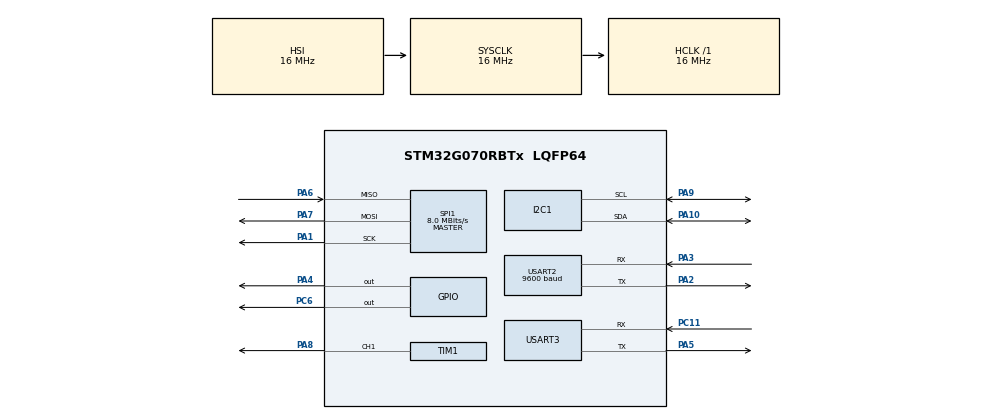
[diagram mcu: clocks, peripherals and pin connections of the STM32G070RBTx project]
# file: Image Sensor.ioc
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Dma.Request0=SPI1_RX
Dma.Request1=SPI1_TX
Dma.SPI1_RX.0.Direction=DMA_PERIPH_TO_MEMORY
Dma.SPI1_RX.0.EventEnable=DISABLE
Dma.SPI1_RX.0.Instance=DMA1_Channel1
Dma.SPI1_RX.0.MemDataAlignment=DMA_MDATAALIGN_BYTE
Dma.SPI1_RX.0.MemInc=DMA_MINC_ENABLE
Dma.SPI1_RX.0.Mode=DMA_NORMAL
Dma.SPI1_RX.0.PeriphDataAlignment=DMA_PDATAALIGN_BYTE
Dma.SPI1_RX.0.PeriphInc=DMA_PINC_DISABLE
Dma.SPI1_RX.0.Polarity=HAL_DMAMUX_REQ_GEN_RISING
Dma.SPI1_RX.0.Priority=DMA_PRIORITY_HIGH
Dma.SPI1_RX.0.RequestNumber=1
Dma.SPI1_RX.0.SignalID=NONE
Dma.SPI1_RX.0.SyncEnable=DISABLE
Dma.SPI1_RX.0.SyncPolarity=HAL_DMAMUX_SYNC_NO_EVENT
Dma.SPI1_RX.0.SyncRequestNumber=1
Dma.SPI1_RX.0.SyncSignalID=NONE
Dma.SPI1_TX.1.Direction=DMA_MEMORY_TO_PERIPH
Dma.SPI1_TX.1.EventEnable=DISABLE
Dma.SPI1_TX.1.Instance=DMA1_Channel2
Dma.SPI1_TX.1.MemDataAlignment=DMA_MDATAALIGN_BYTE
Dma.SPI1_TX.1.MemInc=DMA_MINC_ENABLE
Dma.SPI1_TX.1.Mode=DMA_NORMAL
Dma.SPI1_TX.1.PeriphDataAlignment=DMA_PDATAALIGN_BYTE
Dma.SPI1_TX.1.PeriphInc=DMA_PINC_DISABLE
Dma.SPI1_TX.1.Polarity=HAL_DMAMUX_REQ_GEN_RISING
Dma.SPI1_TX.1.Priority=DMA_PRIORITY_HIGH
Dma.SPI1_TX.1.RequestNumber=1
Dma.SPI1_TX.1.SignalID=NONE
Dma.SPI1_TX.1.SyncEnable=DISABLE
Dma.SPI1_TX.1.SyncPolarity=HAL_DMAMUX_SYNC_NO_EVENT
Dma.SPI1_TX.1.SyncRequestNumber=1
Dma.SPI1_TX.1.SyncSignalID=NONE
Mcu.Family=STM32G0
Mcu.Name=STM32G070RBTx
Mcu.Package=LQFP64
NVIC.DMA1_Channel1_IRQn=true\:0\:0\:false\:false\:true\:false\:true\:true
NVIC.DMA1_Channel2_3_IRQn=true\:0\:0\:false\:false\:true\:false\:true\:true
PA1.Mode=Full_Duplex_Master
PA1.Signal=SPI1_SCK
PA10.Mode=I2C
PA10.Signal=I2C1_SDA
PA2.Mode=Asynchronous
PA2.Signal=USART2_TX
PA3.Mode=Asynchronous
PA3.Signal=USART2_RX
PA4.Signal=GPIO_Output
PA5.Mode=Asynchronous
PA5.Signal=USART3_TX
PA6.Mode=Full_Duplex_Master
PA6.Signal=SPI1_MISO
PA7.Mode=Full_Duplex_Master
PA7.Signal=SPI1_MOSI
PA8.Signal=S_TIM1_CH1
PA9.Mode=I2C
PA9.Signal=I2C1_SCL
PC11.Mode=Asynchronous
PC11.Signal=USART3_RX
PC6.Signal=GPIO_Output
ProjectManager.HeapSize=0x200
ProjectManager.StackSize=0x400
ProjectManager.TargetToolchain=STM32CubeIDE
RCC.ADCFreq_Value=16000000
RCC.AHBFreq_Value=16000000
RCC.CortexFreq_Value=16000000
RCC.EXTERNAL_CLOCK_VALUE=48000
RCC.HCLKFreq_Value=16000000
RCC.HSE_VALUE=8000000
RCC.HSI_VALUE=16000000
RCC.LSE_VALUE=32768
RCC.PLLM=RCC_PLLM_DIV2
RCC.PLLN=20
RCC.PLLR=RCC_PLLR_DIV4
RCC.SYSCLKFreq_VALUE=16000000
RCC.VCOOutputFreq_Value=160000000
SH.S_TIM1_CH1.0=TIM1_CH1,PWM Generation1 CH1
SPI1.BaudRatePrescaler=SPI_BAUDRATEPRESCALER_2
SPI1.CalculateBaudRate=8.0 MBits/s
SPI1.DataSize=SPI_DATASIZE_8BIT
SPI1.Direction=SPI_DIRECTION_2LINES
SPI1.Mode=SPI_MODE_MASTER
SPI1.VirtualType=VM_MASTER
TIM1.Channel-PWM\ Generation1\ CH1=TIM_CHANNEL_1
TIM1.Period=1000-1
TIM1.Prescaler=320-1
TIM1.Pulse-PWM\ Generation1\ CH1=25
TIM3.Period=0xffff-1
TIM3.Prescaler=16-1
USART2.BaudRate=9600
USART2.VirtualMode-Asynchronous=VM_ASYNC
USART3.VirtualMode-Asynchronous=VM_ASYNC
VP_SYS_VS_DBSignals.Mode=DisableDeadBatterySignals
VP_TIM3_VS_ClockSourceINT.Mode=Internal
board=custom

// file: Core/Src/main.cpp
/* USER CODE BEGIN Header */
/**
  ******************************************************************************
  * @file           : main.c
  * @brief          : Main program body
  ******************************************************************************
  * @attention
  *
  * Copyright (c) 2024 STMicroelectronics.
  * All rights reserved.
  *
  * This software is licensed under terms that can be found in the LICENSE file
  * in the root directory of this software component.
  * If no LICENSE file comes with this software, it is provided AS-IS.
  *
  ******************************************************************************
  */
/* USER CODE END Header */
extern "C"{
#include "main.h"
}

/* USER CODE BEGIN Includes */
extern "C"{
#include "stm32g0xx_hal_conf.h"
}
#include <string.h>
#include "../Camera_driver/inc/OV2640_regs.hpp"
#include "../Camera_driver/inc/SPI_camera.hpp"
#include "../Camera_driver/inc/OV2640.hpp"
#include "../App/inc/imager.hpp"
/* USER CODE END Includes */

I2C_HandleTypeDef hi2c1;

SPI_HandleTypeDef hspi1;
DMA_HandleTypeDef hdma_spi1_rx;
DMA_HandleTypeDef hdma_spi1_tx;

TIM_HandleTypeDef htim1;
TIM_HandleTypeDef htim3;

UART_HandleTypeDef huart2;
UART_HandleTypeDef huart3;

void SystemClock_Config(void);
static void MX_GPIO_Init(void);
static void MX_DMA_Init(void);
static void MX_USART2_UART_Init(void);
static void MX_TIM1_Init(void);
static void MX_I2C1_Init(void);
static void MX_SPI1_Init(void);
static void MX_USART3_UART_Init(void);
static void MX_TIM3_Init(void);
/* USER CODE BEGIN PFP */
void Init_SPI_clock(void);
/* USER CODE END PFP */

/* USER CODE BEGIN 0 */
void Image_capture(OV2640 *camera, Imager *imager){
    camera->Capture(500);
    imager->Transmit(camera->Image_data());

    // Turn Off LED
    HAL_GPIO_TogglePin(GPIOB, GPIO_PIN_10);
}
/* USER CODE END 0 */

int main(void)
{

  /* MCU Configuration--------------------------------------------------------*/

  /* Reset of all peripherals, Initializes the Flash interface and the Systick. */
  HAL_Init();

  /* Configure the system clock */
  SystemClock_Config();

  /* Initialize all configured peripherals */
  MX_GPIO_Init();
  MX_DMA_Init();
  MX_USART2_UART_Init();
  MX_TIM1_Init();
  MX_I2C1_Init();
  MX_SPI1_Init();
  MX_USART3_UART_Init();
  MX_TIM3_Init();
  /* USER CODE BEGIN 2 */
  HAL_TIM_PWM_Start(&htim1,TIM_CHANNEL_1);
  HAL_TIM_PWM_Start(&htim1,TIM_CHANNEL_2);
  //HAL_TIM_Base_Start(&htim3);
  HAL_Delay(10);
  Init_SPI_clock();

  // Wait for power stabilization
  HAL_Delay(1000);

  // Initialize exporter
  Imager *imager = new Imager();
  imager->Add_output(&huart2);

  // Initialize camera
  OV2640 *camera = new OV2640(hi2c1, hspi1, SPI_camera::Chip_select_pin{ GPIOA, GPIO_PIN_4 });
  camera->Init(OV2640_640x480_JPEG);

  Image_capture(camera,imager);

  /* USER CODE END 2 */

  /* Infinite loop */
  while (1)
  {

  }
}

void SystemClock_Config(void)
{
  RCC_OscInitTypeDef RCC_OscInitStruct = {0};
  RCC_ClkInitTypeDef RCC_ClkInitStruct = {0};

  /** Configure the main internal regulator output voltage
  */
  HAL_PWREx_ControlVoltageScaling(PWR_REGULATOR_VOLTAGE_SCALE1);

  /** Initializes the RCC Oscillators according to the specified parameters
  * in the RCC_OscInitTypeDef structure.
  */
  RCC_OscInitStruct.OscillatorType = RCC_OSCILLATORTYPE_HSI;
  RCC_OscInitStruct.HSIState = RCC_HSI_ON;
  RCC_OscInitStruct.HSIDiv = RCC_HSI_DIV1;
  RCC_OscInitStruct.HSICalibrationValue = RCC_HSICALIBRATION_DEFAULT;
  RCC_OscInitStruct.PLL.PLLState = RCC_PLL_NONE;
  if (HAL_RCC_OscConfig(&RCC_OscInitStruct) != HAL_OK)
  {
    Error_Handler();
  }

  /** Initializes the CPU, AHB and APB buses clocks
  */
  RCC_ClkInitStruct.ClockType = RCC_CLOCKTYPE_HCLK|RCC_CLOCKTYPE_SYSCLK
                              |RCC_CLOCKTYPE_PCLK1;
  RCC_ClkInitStruct.SYSCLKSource = RCC_SYSCLKSOURCE_HSI;
  RCC_ClkInitStruct.AHBCLKDivider = RCC_SYSCLK_DIV1;
  RCC_ClkInitStruct.APB1CLKDivider = RCC_HCLK_DIV1;

  if (HAL_RCC_ClockConfig(&RCC_ClkInitStruct, FLASH_LATENCY_0) != HAL_OK)
  {
    Error_Handler();
  }
}

static void MX_I2C1_Init(void)
{

  hi2c1.Instance = I2C1;
  hi2c1.Init.Timing = 0x00303D5B;
  hi2c1.Init.OwnAddress1 = 0;
  hi2c1.Init.AddressingMode = I2C_ADDRESSINGMODE_7BIT;
  hi2c1.Init.DualAddressMode = I2C_DUALADDRESS_DISABLE;
  hi2c1.Init.OwnAddress2 = 0;
  hi2c1.Init.OwnAddress2Masks = I2C_OA2_NOMASK;
  hi2c1.Init.GeneralCallMode = I2C_GENERALCALL_DISABLE;
  hi2c1.Init.NoStretchMode = I2C_NOSTRETCH_DISABLE;
  if (HAL_I2C_Init(&hi2c1) != HAL_OK)
  {
    Error_Handler();
  }

  /** Configure Analogue filter
  */
  if (HAL_I2CEx_ConfigAnalogFilter(&hi2c1, I2C_ANALOGFILTER_ENABLE) != HAL_OK)
  {
    Error_Handler();
  }

  /** Configure Digital filter
  */
  if (HAL_I2CEx_ConfigDigitalFilter(&hi2c1, 0) != HAL_OK)
  {
    Error_Handler();
  }

}

static void MX_SPI1_Init(void)
{

  /* SPI1 parameter configuration*/
  hspi1.Instance = SPI1;
  hspi1.Init.Mode = SPI_MODE_MASTER;
  hspi1.Init.Direction = SPI_DIRECTION_2LINES;
  hspi1.Init.DataSize = SPI_DATASIZE_8BIT;
  hspi1.Init.CLKPolarity = SPI_POLARITY_LOW;
  hspi1.Init.CLKPhase = SPI_PHASE_1EDGE;
  hspi1.Init.NSS = SPI_NSS_SOFT;
  hspi1.Init.BaudRatePrescaler = SPI_BAUDRATEPRESCALER_2;
  hspi1.Init.FirstBit = SPI_FIRSTBIT_MSB;
  hspi1.Init.TIMode = SPI_TIMODE_DISABLE;
  hspi1.Init.CRCCalculation = SPI_CRCCALCULATION_DISABLE;
  hspi1.Init.CRCPolynomial = 7;
  hspi1.Init.CRCLength = SPI_CRC_LENGTH_DATASIZE;
  hspi1.Init.NSSPMode = SPI_NSS_PULSE_ENABLE;
  if (HAL_SPI_Init(&hspi1) != HAL_OK)
  {
    Error_Handler();
  }

}

static void MX_TIM1_Init(void)
{

  TIM_MasterConfigTypeDef sMasterConfig = {0};
  TIM_OC_InitTypeDef sConfigOC = {0};
  TIM_BreakDeadTimeConfigTypeDef sBreakDeadTimeConfig = {0};

  htim1.Instance = TIM1;
  htim1.Init.Prescaler = 320-1;
  htim1.Init.CounterMode = TIM_COUNTERMODE_UP;
  htim1.Init.Period = 1000-1;
  htim1.Init.ClockDivision = TIM_CLOCKDIVISION_DIV1;
  htim1.Init.RepetitionCounter = 0;
  htim1.Init.AutoReloadPreload = TIM_AUTORELOAD_PRELOAD_DISABLE;
  if (HAL_TIM_PWM_Init(&htim1) != HAL_OK)
  {
    Error_Handler();
  }
  sMasterConfig.MasterOutputTrigger = TIM_TRGO_RESET;
  sMasterConfig.MasterOutputTrigger2 = TIM_TRGO2_RESET;
  sMasterConfig.MasterSlaveMode = TIM_MASTERSLAVEMODE_DISABLE;
  if (HAL_TIMEx_MasterConfigSynchronization(&htim1, &sMasterConfig) != HAL_OK)
  {
    Error_Handler();
  }
  sConfigOC.OCMode = TIM_OCMODE_PWM1;
  sConfigOC.Pulse = 25;
  sConfigOC.OCPolarity = TIM_OCPOLARITY_HIGH;
  sConfigOC.OCNPolarity = TIM_OCNPOLARITY_HIGH;
  sConfigOC.OCFastMode = TIM_OCFAST_DISABLE;
  sConfigOC.OCIdleState = TIM_OCIDLESTATE_RESET;
  sConfigOC.OCNIdleState = TIM_OCNIDLESTATE_RESET;
  if (HAL_TIM_PWM_ConfigChannel(&htim1, &sConfigOC, TIM_CHANNEL_1) != HAL_OK)
  {
    Error_Handler();
  }
  sBreakDeadTimeConfig.OffStateRunMode = TIM_OSSR_DISABLE;
  sBreakDeadTimeConfig.OffStateIDLEMode = TIM_OSSI_DISABLE;
  sBreakDeadTimeConfig.LockLevel = TIM_LOCKLEVEL_OFF;
  sBreakDeadTimeConfig.DeadTime = 0;
  sBreakDeadTimeConfig.BreakState = TIM_BREAK_DISABLE;
  sBreakDeadTimeConfig.BreakPolarity = TIM_BREAKPOLARITY_HIGH;
  sBreakDeadTimeConfig.BreakFilter = 0;
  sBreakDeadTimeConfig.BreakAFMode = TIM_BREAK_AFMODE_INPUT;
  sBreakDeadTimeConfig.Break2State = TIM_BREAK2_DISABLE;
  sBreakDeadTimeConfig.Break2Polarity = TIM_BREAK2POLARITY_HIGH;
  sBreakDeadTimeConfig.Break2Filter = 0;
  sBreakDeadTimeConfig.Break2AFMode = TIM_BREAK_AFMODE_INPUT;
  sBreakDeadTimeConfig.AutomaticOutput = TIM_AUTOMATICOUTPUT_DISABLE;
  if (HAL_TIMEx_ConfigBreakDeadTime(&htim1, &sBreakDeadTimeConfig) != HAL_OK)
  {
    Error_Handler();
  }
  HAL_TIM_MspPostInit(&htim1);

}

static void MX_TIM3_Init(void)
{

  TIM_ClockConfigTypeDef sClockSourceConfig = {0};
  TIM_MasterConfigTypeDef sMasterConfig = {0};

  htim3.Instance = TIM3;
  htim3.Init.Prescaler = 16-1;
  htim3.Init.CounterMode = TIM_COUNTERMODE_UP;
  htim3.Init.Period = 0xffff-1;
  htim3.Init.ClockDivision = TIM_CLOCKDIVISION_DIV1;
  htim3.Init.AutoReloadPreload = TIM_AUTORELOAD_PRELOAD_DISABLE;
  if (HAL_TIM_Base_Init(&htim3) != HAL_OK)
  {
    Error_Handler();
  }
  sClockSourceConfig.ClockSource = TIM_CLOCKSOURCE_INTERNAL;
  if (HAL_TIM_ConfigClockSource(&htim3, &sClockSourceConfig) != HAL_OK)
  {
    Error_Handler();
  }
  sMasterConfig.MasterOutputTrigger = TIM_TRGO_RESET;
  sMasterConfig.MasterSlaveMode = TIM_MASTERSLAVEMODE_DISABLE;
  if (HAL_TIMEx_MasterConfigSynchronization(&htim3, &sMasterConfig) != HAL_OK)
  {
    Error_Handler();
  }

}

static void MX_USART2_UART_Init(void)
{

  huart2.Instance = USART2;
  huart2.Init.BaudRate = 9600;
  huart2.Init.WordLength = UART_WORDLENGTH_8B;
  huart2.Init.StopBits = UART_STOPBITS_1;
  huart2.Init.Parity = UART_PARITY_NONE;
  huart2.Init.Mode = UART_MODE_TX_RX;
  huart2.Init.HwFlowCtl = UART_HWCONTROL_NONE;
  huart2.Init.OverSampling = UART_OVERSAMPLING_16;
  huart2.Init.OneBitSampling = UART_ONE_BIT_SAMPLE_DISABLE;
  huart2.Init.ClockPrescaler = UART_PRESCALER_DIV1;
  huart2.AdvancedInit.AdvFeatureInit = UART_ADVFEATURE_NO_INIT;
  if (HAL_UART_Init(&huart2) != HAL_OK)
  {
    Error_Handler();
  }
  if (HAL_UARTEx_SetTxFifoThreshold(&huart2, UART_TXFIFO_THRESHOLD_1_8) != HAL_OK)
  {
    Error_Handler();
  }
  if (HAL_UARTEx_SetRxFifoThreshold(&huart2, UART_RXFIFO_THRESHOLD_1_8) != HAL_OK)
  {
    Error_Handler();
  }
  if (HAL_UARTEx_DisableFifoMode(&huart2) != HAL_OK)
  {
    Error_Handler();
  }

}

static void MX_USART3_UART_Init(void)
{

  huart3.Instance = USART3;
  huart3.Init.BaudRate = 115200;
  huart3.Init.WordLength = UART_WORDLENGTH_8B;
  huart3.Init.StopBits = UART_STOPBITS_1;
  huart3.Init.Parity = UART_PARITY_NONE;
  huart3.Init.Mode = UART_MODE_TX_RX;
  huart3.Init.HwFlowCtl = UART_HWCONTROL_NONE;
  huart3.Init.OverSampling = UART_OVERSAMPLING_16;
  huart3.Init.OneBitSampling = UART_ONE_BIT_SAMPLE_DISABLE;
  huart3.Init.ClockPrescaler = UART_PRESCALER_DIV1;
  huart3.AdvancedInit.AdvFeatureInit = UART_ADVFEATURE_NO_INIT;
  if (HAL_UART_Init(&huart3) != HAL_OK)
  {
    Error_Handler();
  }

}

static void MX_DMA_Init(void)
{

  /* DMA controller clock enable */
  __HAL_RCC_DMA1_CLK_ENABLE();

  /* DMA interrupt init */
  /* DMA1_Channel1_IRQn interrupt configuration */
  HAL_NVIC_SetPriority(DMA1_Channel1_IRQn, 0, 0);
  HAL_NVIC_EnableIRQ(DMA1_Channel1_IRQn);
  /* DMA1_Channel2_3_IRQn interrupt configuration */
  HAL_NVIC_SetPriority(DMA1_Channel2_3_IRQn, 0, 0);
  HAL_NVIC_EnableIRQ(DMA1_Channel2_3_IRQn);

}

static void MX_GPIO_Init(void)
{
  GPIO_InitTypeDef GPIO_InitStruct = {0};

  /* GPIO Ports Clock Enable */
  __HAL_RCC_GPIOC_CLK_ENABLE();
  __HAL_RCC_GPIOA_CLK_ENABLE();
  __HAL_RCC_GPIOB_CLK_ENABLE();

  /*Configure GPIO pin Output Level */
  HAL_GPIO_WritePin(GPIOB, GPIO_PIN_10, GPIO_PIN_RESET);

  /*Configure GPIO pin : PB10 */
  GPIO_InitStruct.Pin = GPIO_PIN_10;
  GPIO_InitStruct.Mode = GPIO_MODE_OUTPUT_PP;
  GPIO_InitStruct.Pull = GPIO_NOPULL;
  GPIO_InitStruct.Speed = GPIO_SPEED_FREQ_LOW;
  HAL_GPIO_Init(GPIOB, &GPIO_InitStruct);

}

/* USER CODE BEGIN 4 */

void CS_HIGH(void)
{
	//need to determine which pin is connected to CS
	HAL_GPIO_WritePin(GPIOA,GPIO_PIN_4,GPIO_PIN_SET);
}

void CS_LOW(void)
{
	//need to determine which pin is connected to CS
	HAL_GPIO_WritePin(GPIOA,GPIO_PIN_4,GPIO_PIN_SET);
}

void delay_us(uint16_t us){
	//using 20 Mhz will create a low value of 50ns
	__HAL_TIM_SET_COUNTER(&htim3,0);
	while(__HAL_TIM_GET_COUNTER(&htim3) < us);
}

void Init_SPI_clock(){
    uint8_t empty = 0x00;
    HAL_GPIO_WritePin(GPIOB, GPIO_PIN_10, GPIO_PIN_RESET);
    HAL_SPI_Transmit(&hspi1, &empty, 1, HAL_MAX_DELAY);
    HAL_SPI_Receive(&hspi1, (uint8_t *) &empty, 1, HAL_MAX_DELAY);
    HAL_GPIO_WritePin(GPIOB, GPIO_PIN_10, GPIO_PIN_SET);
}

//delete from here
/* USER CODE END 4 */

void Error_Handler(void)
{
  __disable_irq();
  while (1)
  {
  }
}
